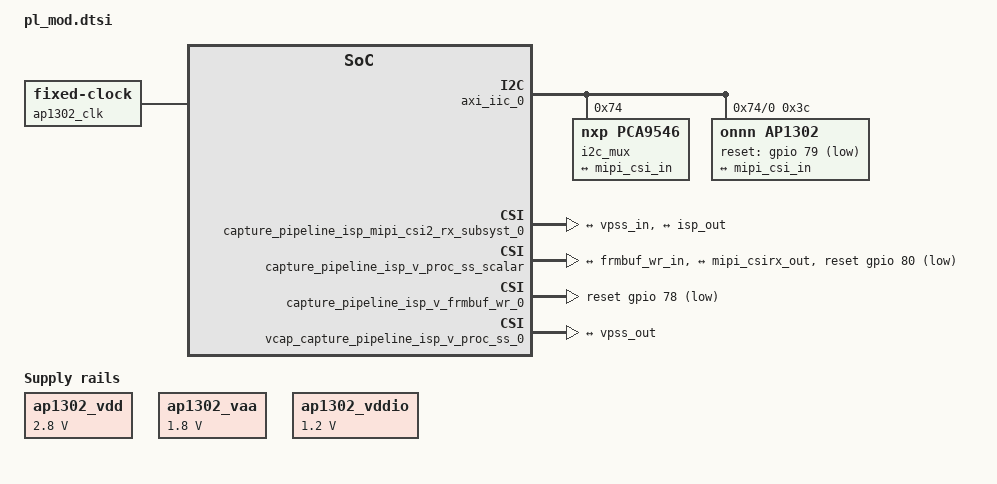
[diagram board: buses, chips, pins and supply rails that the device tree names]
/*
 * CAUTION: This file is automatically generated by Xilinx.
 * Version: XSCT 
 * Today is: Mon Dec 29 19:48:29 2025
 */


/dts-v1/;
/plugin/;
/ {
	fragment@0 {
		target = <&fpga_full>;
		overlay0: __overlay__ {
			#address-cells = <2>;
			#size-cells = <2>;
			firmware-name = "camera_wrapper.bit.bin";
			pid = <0x0>;
			resets = <&zynqmp_reset 116>;
			uid = <0x96743f64>;
		};
	};
	fragment@1 {
		target = <&amba>;
		overlay1: __overlay__ {
			afi0: afi0 {
				compatible = "xlnx,afi-fpga";
				config-afi = < 0 0>, <1 0>, <2 0>, <3 0>, <4 1>, <5 1>, <6 0>, <7 0>, <8 1>, <9 1>, <10 2>, <11 2>, <12 2>, <13 2>, <14 0x0>, <15 0x000>;
			};
			clocking0: clocking0 {
				#clock-cells = <0>;
				assigned-clock-rates = <99999001>;
				assigned-clocks = <&zynqmp_clk 71>;
				clock-output-names = "fabric_clk";
				clocks = <&zynqmp_clk 71>;
				compatible = "xlnx,fclk";
			};
		};
	};
	fragment@2 {
		target = <&amba>;
		overlay2: __overlay__ {
			#address-cells = <2>;
			#size-cells = <2>;

			ap1302_clk: sensor_clk {
				#clock-cells = <0x0>;
				compatible = "fixed-clock";
				clock-frequency = <0x48000000>;
			};
			ap1302_vdd: fixedregulator@0 {
				compatible = "regulator-fixed";
				regulator-name = "ap1302_vdd";
				regulator-min-microvolt = <2800000>;
				regulator-max-microvolt = <2800000>;
				enable-active-high;
			};
			ap1302_vaa: fixedregulator@1 {
				compatible = "regulator-fixed";
				regulator-name = "ap1302_vaa";
				regulator-min-microvolt = <1800000>;
				regulator-max-microvolt = <1800000>;
			};
			ap1302_vddio: fixedregulator@2 {
				compatible = "regulator-fixed";
				regulator-name = "ap1302_vddio";
				regulator-min-microvolt = <1200000>;
				regulator-max-microvolt = <1200000>;
			};

			axi_iic_0: i2c@80010000 {
				#address-cells = <1>;
				#size-cells = <0>;
				clock-names = "s_axi_aclk";
				clocks = <&misc_clk_0>;
				compatible = "xlnx,axi-iic-2.1", "xlnx,xps-iic-2.00.a";
				interrupt-names = "iic2intc_irpt";
				interrupt-parent = <&gic>;
				interrupts = <0 107 4>;
				reg = <0x0 0x80010000 0x0 0x10000>;


				i2c_mux: i2c-mux@74 {
					compatible = "nxp,pca9546";
					reg = <0x74>;
					i2c@0 {
						#address-cells = <1>;
						#size-cells = <0>;
						reg = <0>;
						ap1302: isp@3c {
							compatible = "onnn,ap1302";
							reg = <0x3c>;
							#address-cells = <1>;
							#size-cells = <0>;
							reset-gpios = <&gpio 79 1>;
							clocks = <&ap1302_clk>;
							sensors {
								#address-cells = <1>;
								#size-cells = <0>;
								onnn,model = "onnn,ar1335";
								sensor@0 {
									reg = <0>;
									vdd-supply = <&ap1302_vdd>;
									vaa-supply = <&ap1302_vaa>;
									vddio-supply = <&ap1302_vddio>;
								};
							};
							ports {
								#address-cells = <1>;
								#size-cells = <0>;
								port@0 {
									reg = <2>;
									isp_out: endpoint {
										remote-endpoint = <&mipi_csi_in>;
										data-lanes = <1 2 3 4>;
										};
								};
							};
						};
					};
				};
			};
			misc_clk_0: misc_clk_0 {
				#clock-cells = <0>;
				clock-frequency = <99999000>;
				compatible = "fixed-clock";
			};
			capture_pipeline_isp_mipi_csi2_rx_subsyst_0: mipi_csi2_rx_subsystem@80000000 {
				clock-names = "lite_aclk", "dphy_clk_200M", "video_aclk";
				clocks = <&misc_clk_0>, <&misc_clk_1>, <&misc_clk_1>;
				compatible = "xlnx,mipi-csi2-rx-subsystem-5.3", "xlnx,mipi-csi2-rx-subsystem-5.0";
				interrupt-names = "csirxss_csi_irq";
				interrupt-parent = <&gic>;
				interrupts = <0 104 4>;
				reg = <0x0 0x80000000 0x0 0x1000>;
				xlnx,axis-tdata-width = <32>;
				xlnx,csi-pxl-format = <0x1e>;
				xlnx,en-active-lanes;
				xlnx,max-lanes = <4>;
				xlnx,ppc = <1>;
				xlnx,vfb ;
				mipi_csi_ports: ports {
					#address-cells = <1>;
					#size-cells = <0>;
					mipi_csi_port1: port@1 {
						/* Fill cfa-pattern=rggb for raw data types, other fields video-format and video-width user needs to fill */
						reg = <1>;
						mipi_csirx_out: endpoint {
							remote-endpoint = <&vpss_in>;
						};
					};
					mipi_csi_port0: port@0 {
						/* Fill cfa-pattern=rggb for raw data types, other fields video-format,video-width user needs to fill */
						/* User need to add something like remote-endpoint=<&out> under the node csiss_in:endpoint */
						reg = <0>;
						mipi_csi_in: endpoint {
							data-lanes = <1 2 3 4>;
							remote-endpoint = <&isp_out>;
						};
					};
				};
			};
			misc_clk_1: misc_clk_1 {
				#clock-cells = <0>;
				clock-frequency = <199998000>;
				compatible = "fixed-clock";
			};

			capture_pipeline_isp_v_proc_ss_scalar: v_proc_ss@b0040000 {
				clock-names = "aclk_axis", "aclk_ctrl";
				clocks = <&misc_clk_1>, <&misc_clk_1>;
				compatible = "xlnx,v-proc-ss-2.3", "xlnx,vpss-scaler-2.2", "xlnx,v-vpss-scaler-2.2", "xlnx,vpss-scaler";
				reg = <0x0 0xb0040000 0x0 0x40000>;
				reset-gpios = <&gpio 80 1>;
				xlnx,colorspace-support = <0>;
				xlnx,csc-enable-window = "true";
				xlnx,enable-csc = "true";
				xlnx,h-scaler-phases = <64>;
				xlnx,h-scaler-taps = <6>;
				xlnx,max-height = <1080>;
				xlnx,max-num-phases = <64>;
				xlnx,max-width = <1920>;
				xlnx,num-hori-taps = <6>;
				xlnx,num-vert-taps = <6>;
				xlnx,pix-per-clk = <1>;
				xlnx,samples-per-clk = <1>;
				xlnx,scaler-algorithm = <2>;
				xlnx,topology = <0>;
				xlnx,use-uram = <0>;
				xlnx,v-scaler-phases = <64>;
				xlnx,v-scaler-taps = <6>;
				xlnx,video-width = <8>;
				scaler_portscapture_pipeline_isp_v_proc_ss_scalar: ports {
					#address-cells = <1>;
					#size-cells = <0>;
					scaler_port1capture_pipeline_isp_v_proc_ss_scalar: port@1 {
						/* For xlnx,video-format user needs to fill as per their requirement */
						reg = <1>;
						xlnx,video-format = <3>;
						xlnx,video-width = <8>;
						vpss_out: endpoint {
							remote-endpoint = <&frmbuf_wr_in>;
						};
					};
					scaler_port0capture_pipeline_isp_v_proc_ss_scalar: port@0 {
						/* For xlnx,video-format user needs to fill as per their requirement */
						reg = <0>;
						xlnx,video-format = <0>;
						xlnx,video-width = <8>;
						vpss_in: endpoint {
							remote-endpoint = <&mipi_csirx_out>;
						};
					};
				};
			};
            capture_pipeline_isp_v_frmbuf_wr_0: v_frmbuf_wr@b0000000 {
				#dma-cells = <1>;
				clock-names = "ap_clk";
				clocks = <&misc_clk_1>;
				compatible = "xlnx,v-frmbuf-wr-2.4", "xlnx,axi-frmbuf-wr-v2.2";
				interrupt-names = "interrupt";
				interrupt-parent = <&gic>;
				interrupts = <0 105 4>;
				reg = <0x0 0xb0000000 0x0 0x10000>;
				reset-gpios = <&gpio 78 1>;
				xlnx,dma-addr-width = <32>;
				xlnx,dma-align = <8>;
				xlnx,max-height = <1080>;
				xlnx,max-width = <1920>;
				xlnx,pixels-per-clock = <1>;
				xlnx,s-axi-ctrl-addr-width = <0x7>;
				xlnx,s-axi-ctrl-data-width = <0x20>;
				xlnx,vid-formats = "rgb888", "bgr888", "nv12";
				xlnx,video-width = <8>;
			};
			zyxclmm_drm {
				compatible = "xlnx,zocl";
			};
			vcap_capture_pipeline_isp_v_proc_ss_0 {
				compatible = "xlnx,video";
				dma-names = "port0";
				dmas = <&capture_pipeline_isp_v_frmbuf_wr_0 0>;
				vcap_ports: ports {
					#address-cells = <1>;
					#size-cells = <0>;
					vcap_port: port@0 {
						direction = "input";
						reg = <0>;
						frmbuf_wr_in: endpoint {
							remote-endpoint = <&vpss_out>;
						};
					};
				};
			};
		};
	};
};
